# S32K118 register map
Vendor: NXP; Series: S32K; File version: 1.6
CPU: CM0PLUS r0p0, little endian, MPU, FPU, 2 interrupt priority bits
Registers are 32-bit, read-write, reset 0x0 unless marked. A register's access mark holds for its fields unless they carry their own. Offsets are from the block's base; [hi:lo] are bit positions; 'fields as' and 'values as' point back to an identical list.

## MSCM
Base 0x40001000; register names take the prefix MSCM_
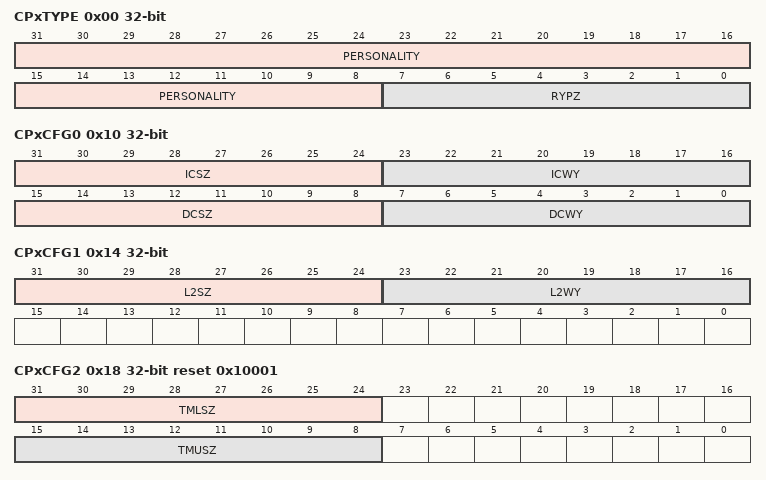
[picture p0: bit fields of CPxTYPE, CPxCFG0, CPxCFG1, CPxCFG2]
0x00 CPxTYPE ro reset not defined — Processor X Type Register
  [31:8] PERSONALITY — Processor x Personality
  [7:0] RYPZ — Processor x Revision
0x04 CPxNUM ro (reset mask 0xFFFFFFFE) — Processor X Number Register
  [0] CPN — Processor x Number
0x08 CPxMASTER ro (reset mask 0xFFFFFFC0) — Processor X Master Register
  [5:0] PPMN — Processor x Physical Master Number
0x0C CPxCOUNT ro — Processor X Count Register
  [1:0] PCNT — Processor Count
0x10 CPxCFG0 ro reset not defined — Processor X Configuration Register 0
  [31:24] ICSZ — Level 1 Instruction Cache Size
  [23:16] ICWY — Level 1 Instruction Cache Ways
  [15:8] DCSZ — Level 1 Data Cache Size
  [7:0] DCWY — Level 1 Data Cache Ways
0x14 CPxCFG1 ro (reset mask 0xFFFF) — Processor X Configuration Register 1
  [31:24] L2SZ — Level 2 Instruction Cache Size
  [23:16] L2WY — Level 2 Instruction Cache Ways
0x18 CPxCFG2 ro reset 0x10001 (reset mask 0xFF00FF) — Processor X Configuration Register 2
  [31:24] TMLSZ — Tightly-coupled Memory Lower Size
  [15:8] TMUSZ — Tightly-coupled Memory Upper Size
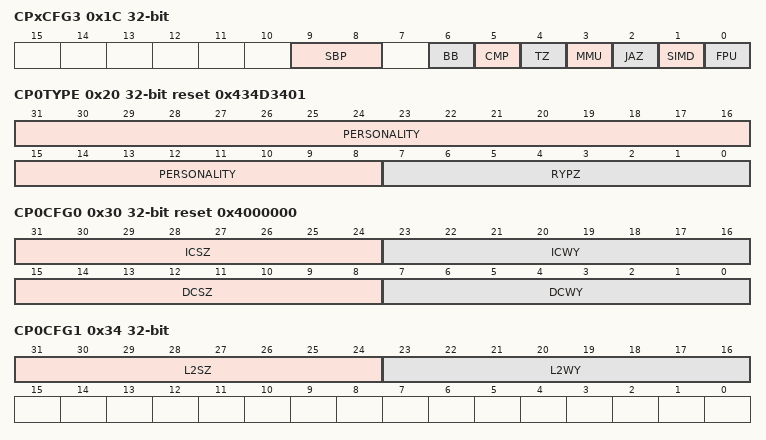
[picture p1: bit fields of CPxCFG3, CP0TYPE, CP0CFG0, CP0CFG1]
0x1C CPxCFG3 ro (reset mask 0xFFFFFC80) — Processor X Configuration Register 3
  [9:8] SBP — System Bus Ports
  [6] BB — Bit Banding
    0=Bit Banding is not supported; 1=Bit Banding is supported
  [5] CMP — Core Memory Protection unit
    0=Core Memory Protection is not included; 1=Core Memory Protection is included
  [4] TZ — Trust Zone
    0=Trust Zone support is not included; 1=Trust Zone support is included
  [3] MMU — Memory Management Unit
    0=MMU support is not included; 1=MMU support is included
  [2] JAZ — Jazelle support
    0=Jazelle support is not included; 1=Jazelle support is included
  [1] SIMD — SIMD/NEON instruction support
    0=SIMD/NEON support is not included; 1=SIMD/NEON support is included
  [0] FPU — Floating Point Unit
    0=FPU support is not included; 1=FPU support is included
0x20 CP0TYPE ro reset 0x434D3401 — Processor 0 Type Register
  [31:8] PERSONALITY — Processor 0 Personality
  [7:0] RYPZ — Processor 0 Revision
0x24 CP0NUM ro — Processor 0 Number Register
  [0] CPN — Processor 0 Number
0x28 CP0MASTER ro — Processor 0 Master Register
  [5:0] PPMN — Processor 0 Physical Master Number
0x2C CP0COUNT ro — Processor 0 Count Register
  [1:0] PCNT — Processor Count
0x30 CP0CFG0 ro reset 0x4000000 — Processor 0 Configuration Register 0
  fields as CPxCFG0
0x34 CP0CFG1 ro — Processor 0 Configuration Register 1
  fields as CPxCFG1
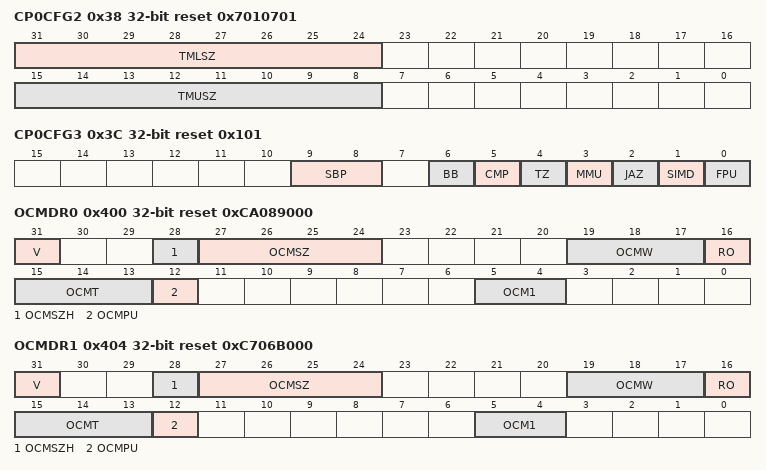
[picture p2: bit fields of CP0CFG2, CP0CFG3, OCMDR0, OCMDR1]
0x38 CP0CFG2 ro reset 0x7010701 — Processor 0 Configuration Register 2
  fields as CPxCFG2
0x3C CP0CFG3 ro reset 0x101 — Processor 0 Configuration Register 3
  fields as CPxCFG3
0x400 OCMDR0 reset 0xCA089000 — On-Chip Memory Descriptor Register
  [31] V ro
    0=OCMEMn is not present; 1=OCMEMn is present
  [28] OCMSZH ro
    0=OCMEMn is a power-of-2 capacity; 1=OCMEMn is not a power-of-2, with a capacity is 0.75 * OCMSZ
  [27:24] OCMSZ ro
    0=no OCMEMn; 1=1KB OCMEMn; 2=2KB OCMEMn; 3=4KB OCMEMn; 4=8KB OCMEMn; 5=16KB OCMEMn; 6=32KB OCMEMn; 7=64KB OCMEMn; 8=128KB OCMEMn; 9=256KB OCMEMn; 10=512KB OCMEMn; 11=1MB OCMEMn; 12=2MB OCMEMn; 13=4MB OCMEMn; 14=8MB OCMEMn; 15=16MB OCMEMn
  [19:17] OCMW ro
    2=OCMEMn 32-bits wide; 3=OCMEMn 64-bits wide; 4=OCMEMn 128-bits wide; 5=OCMEMn 256-bits wide
  [16] RO
    0=Writes to the OCMDRn[11:0] are allowed; 1=Writes to the OCMDRn[11:0] are ignored
  [15:13] OCMT ro
    4=OCMEMn is a Program Flash; 5=OCMEMn is a Data Flash; 6=OCMEMn is an EEE
  [12] OCMPU ro
  [5:4] OCM1 — OCMEM Control Field 1
0x404 OCMDR1 reset 0xC706B000 — On-Chip Memory Descriptor Register
  fields as OCMDR0
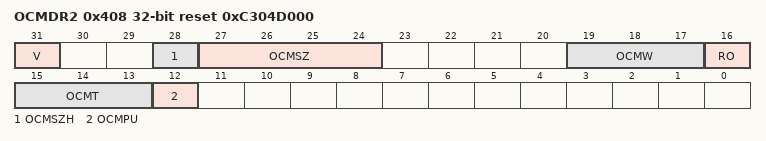
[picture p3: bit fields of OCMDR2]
0x408 OCMDR2 reset 0xC304D000 — On-Chip Memory Descriptor Register
  [31] V ro
    0=OCMEMn is not present; 1=OCMEMn is present
  [28] OCMSZH ro
    values as OCMDR0.OCMSZH
  [27:24] OCMSZ ro
    values as OCMDR0.OCMSZ
  [19:17] OCMW ro
    values as OCMDR0.OCMW
  [16] RO
    values as OCMDR0.RO
  [15:13] OCMT ro
    values as OCMDR0.OCMT
  [12] OCMPU ro

## Notices in the file
Redistribution and use in source and binary forms, with or without modification,
are permitted provided that the following conditions are met:
o Redistributions of source code must retain the above copyright notice, this list
of conditions and the following disclaimer.
o Redistributions in binary form must reproduce the above copyright notice, this
list of conditions and the following disclaimer in the documentation and/or
other materials provided with the distribution.
o Neither the name of Freescale Semiconductor, Inc. nor the names of its
contributors may be used to endorse or promote products derived from this
software without specific prior written permission.
THIS SOFTWARE IS PROVIDED BY THE COPYRIGHT HOLDERS AND CONTRIBUTORS "AS IS" AND
ANY EXPRESS OR IMPLIED WARRANTIES, INCLUDING, BUT NOT LIMITED TO, THE IMPLIED
WARRANTIES OF MERCHANTABILITY AND FITNESS FOR A PARTICULAR PURPOSE ARE
DISCLAIMED. IN NO EVENT SHALL THE COPYRIGHT HOLDER OR CONTRIBUTORS BE LIABLE FOR
ANY DIRECT, INDIRECT, INCIDENTAL, SPECIAL, EXEMPLARY, OR CONSEQUENTIAL DAMAGES
(INCLUDING, BUT NOT LIMITED TO, PROCUREMENT OF SUBSTITUTE GOODS OR SERVICES;
LOSS OF USE, DATA, OR PROFITS; OR BUSINESS INTERRUPTION) HOWEVER CAUSED AND ON
ANY THEORY OF LIABILITY, WHETHER IN CONTRACT, STRICT LIABILITY, OR TORT
(INCLUDING NEGLIGENCE OR OTHERWISE) ARISING IN ANY WAY OUT OF THE USE OF THIS
SOFTWARE, EVEN IF ADVISED OF THE POSSIBILITY OF SUCH DAMAGE.
